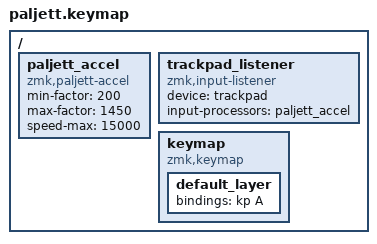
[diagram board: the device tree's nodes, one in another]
#include <behaviors.dtsi>
#include <dt-bindings/zmk/keys.h>
#include <input/processors.dtsi>

/ {
    paljett_accel: paljett_accel {
        compatible = "zmk,paljett-accel";
        status = "okay";
        #input-processor-cells = <0>;
        min-factor = <200>;
        max-factor = <1450>;
        speed-max = <15000>;
    };

    trackpad_listener: trackpad_listener {
        compatible = "zmk,input-listener";
        status = "okay";
        device = <&trackpad>;
        input-processors = <&paljett_accel>;
    };

    keymap {
        compatible = "zmk,keymap";
        default_layer {
            bindings = <&kp A>;
        };
    };
};
